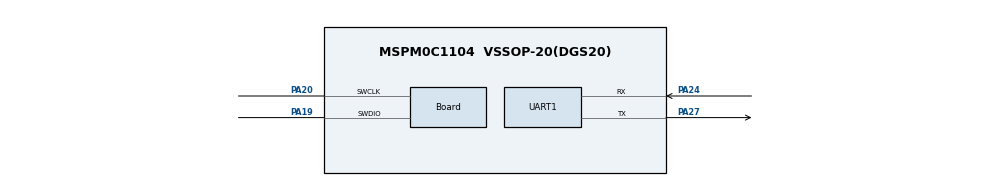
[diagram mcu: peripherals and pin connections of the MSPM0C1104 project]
//@cliArgs --device "MSPM0C110X" --package "VSSOP-20(DGS20)" --part "Default"
//@v2CliArgs --device "MSPM0C1104" --package "VSSOP-20(DGS20)"
// @cliArgs --board /ti/boards/LP_MSPM0C1104 --rtos nortos

/**
 * Import the modules used in this configuration.
 */
const GPIO          = scripting.addModule("/ti/driverlib/GPIO", {}, false);
const GPIO1         = GPIO.addInstance();
const GPIO2         = GPIO.addInstance();
const GPIO3         = GPIO.addInstance();
const UART          = scripting.addModule("/ti/driverlib/UART", {}, false);
const UART1         = UART.addInstance();
const ProjectConfig = scripting.addModule("/ti/project_config/ProjectConfig");

/**
 * Write custom configuration values to the imported modules.
 */
GPIO1.$name                              = "GPIO_Button";
GPIO1.associatedPins[0].$name            = "PIN_0";
GPIO1.associatedPins[0].assignedPort     = "PORTA";
GPIO1.associatedPins[0].direction        = "INPUT";
GPIO1.associatedPins[0].internalResistor = "PULL_UP";
GPIO1.associatedPins[0].assignedPin      = "16";

const Board                       = scripting.addModule("/ti/driverlib/Board", {}, false);
Board.configureUnused             = true;
Board.peripheral.$assign          = "DEBUGSS";
Board.peripheral.swclkPin.$assign = "PA20";
Board.peripheral.swdioPin.$assign = "PA19";

GPIO2.$name                          = "GPIO_BSL";
GPIO2.associatedPins.create(2);
GPIO2.associatedPins[0].$name        = "NRST";
GPIO2.associatedPins[0].assignedPort = "PORTA";
GPIO2.associatedPins[0].assignedPin  = "2";
GPIO2.associatedPins[1].$name        = "Invoke";
GPIO2.associatedPins[1].assignedPort = "PORTA";
GPIO2.associatedPins[1].assignedPin  = "4";

GPIO3.$name                          = "GPIO_LED";
GPIO3.associatedPins[0].assignedPort = "PORTA";
GPIO3.associatedPins[0].$name        = "Error";
GPIO3.associatedPins[0].assignedPin  = "22";

const SYSCTL       = scripting.addModule("/ti/driverlib/SYSCTL", {}, false);
SYSCTL.powerPolicy = "STANDBY0";
SYSCTL.clockTreeEn = true;

UART1.$name                    = "UART_0";
UART1.enabledInterrupts        = ["RX"];
UART1.peripheral.rxPin.$assign = "PA24";
UART1.peripheral.txPin.$assign = "PA27";

ProjectConfig.deviceSpin = "MSPM0C1104";
scripting.suppress("Migrating requires going through the Switch Board or Device menu in the Device View section\\.", ProjectConfig, "deviceSpin");
